# RT584ZCM33 register map
Series: ARMv8-M Mainline; File version: 1.0
CPU: CM33 r0p0, little endian, MPU, no FPU, VTOR, 3 interrupt priority bits
Registers are 32-bit, read-write, reset 0x0 unless marked. A register's access mark holds for its fields unless they carry their own. Offsets are from the block's base; [hi:lo] are bit positions.

## I2C_S_Non-Secure — I2C_S Non-Secure Register block
Base 0x40018000
Same registers: I2C_S_Secure 0x50018000
0x00 I2CS_RWDATA_REG — i2cs rwdata
  [7:0] rx_data ro — Received Data
    0=B_0_to_7 (Received Data)
  [7:0] tx_data wo — Data To be transmitted
0x04 I2CS_ADDR_REG — i2cs addr
  [7:1] slv_addr — I2C Slave address
    0=B_1_to_7 (I2C Slave address)
0x08 I2CS_IER_REG — i2cs ier
  [5:0] i2cs_intr_en — Enable of interrupts. Set 1 to enable intr_status trigger interrupts. [0] Address Match Interrupt. [1] Data Ready Interrupt. [2] bus_stop Interrupt. [3] Timeout Interrupt. [4] NA [5] NA
    0=B_0_to_5 (Enable of interrupts. Set 1 to enable intr_status trigger interrupts. [0] Address Match Interrupt. [1] Data Ready Interrupt. [2] bus_stop Interrupt. [3] Timeout Interrupt. [4] NA [5] NA)
0x0C I2CS_ISR_REG — i2cs isr
  [5:0] i2cs_intr_status ro — Status of interrupts. These bits still work even when intr_en=0 [0] Address Match Interrupt. [1] Data Ready Interrupt. [2] bus_stop Interrupt. [3] Timeout Interrupt. [4] NA [5] NA
    0=B_0_to_5 (Status of interrupts. These bits still work even when intr_en=0 [0] Address Match Interrupt. [1] Data Ready Interrupt. [2] bus_stop Interrupt. [3] Timeout Interrupt. [4] NA [5] NA)
  [5:0] i2cs_intr_clr wo — Interrupts clear signal. Write 1 to clear intr_status for each bit
    0=B_0_to_5 (Interrupts clear signal. Write 1 to clear intr_status for each bit)
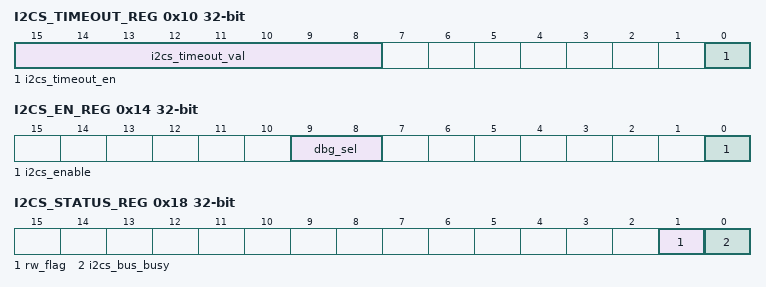
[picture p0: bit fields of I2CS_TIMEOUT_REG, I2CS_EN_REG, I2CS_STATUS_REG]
0x10 I2CS_TIMEOUT_REG — i2cs timeout
  [15:8] i2cs_timeout_val — Timeout value = (1 + timeout_val) ms
    0=B_8_to_15 (Timeout value = (1 + timeout_val) ms)
  [0] i2cs_timeout_en — Enable timeout function when SCL being not changed for 1~256ms
    0=B_0 (Enable timeout function when SCL being not changed for 1~256ms)
0x14 I2CS_EN_REG — i2cs en
  [9:8] dbg_sel — debug sel
    0=B_8_to_9 (debug sel)
  [0] i2cs_enable — Set 1 to start I2C after all above setting is ready.
    0=B_0 (Set 1 to start I2C after all above setting is ready.)
0x18 I2CS_STATUS_REG ro — i2cs status
  [1] rw_flag — Read/Write flag of I2C spec. 0: write 1: read
    0=B_1_ITEM0 (write); 1=B_1_ITEM1 (read)
  [0] i2cs_bus_busy — busy. Assert when bus start detected. Deassert when bus stop detected.
    0=B_0 (busy. Assert when bus start detected. Deassert when bus stop detected.)

## xDMA_Non-Secure — xDMA Non-Secure Register block
Base 0x40028000
Same registers: xDMA_Secure 0x50028000
0x00 CTL0_REG reset 0x1 — ctl0
  [0] cfg_xdma_en — Enable XDMA 0: disable 1: enable
    0=B_0_ITEM0 (disable); 1=B_0_ITEM1 (enable)
0x04 CTL1_REG wo — ctl1
  [0] cfg_xdma_rst — Reset XDMA 0: disable 1: reset
    0=B_0 (Reset XDMA 0: disable 1: reset)

## DMA0_Non-Secure — DMA0 Non-Secure Register block
Base 0x40029000
Same registers: DMA1_Non-Secure 0x4002A000, DMA0_Secure 0x50029000, DMA1_Secure 0x5002A000
0x00 READ_SRC_ADDR_REG — read source address
0x04 WRITE_DES_ADDR_REG — write desination address
0x08 MOVE_BYTE_COUNT_REG reset 0x1 — move byte, need >= 1
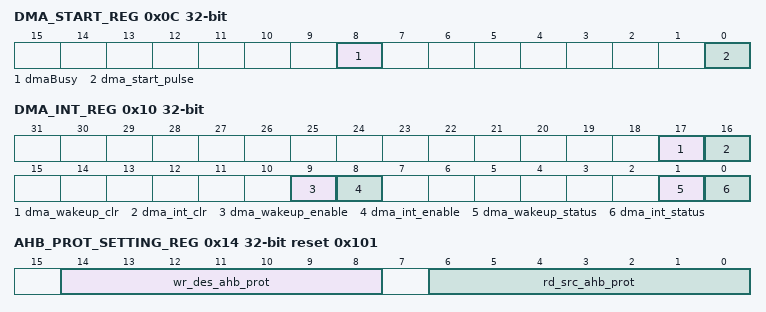
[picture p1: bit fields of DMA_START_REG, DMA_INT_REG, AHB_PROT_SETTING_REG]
0x0C DMA_START_REG — dma start
  [8] dmaBusy ro
    0=B_8 (dma busy)
  [0] dma_start_pulse wo — start engine
    0=B_0 (start engine)
0x10 DMA_INT_REG — dma int
  [17] dma_wakeup_clr wo — wakeup clear
    0=B_17 (wakeup clear)
  [16] dma_int_clr wo — interrupt clear
    0=B_16 (interrupt clear)
  [9] dma_wakeup_enable — wakeup enable
    0=B_9 (wakeup enable)
  [8] dma_int_enable — interrupt enable
    0=B_8 (interrupt enable)
  [1] dma_wakeup_status ro — wakeup status
    0=B_1 (wakeup status)
  [0] dma_int_status ro — interrupt status
    0=B_0 (interrupt status)
0x14 AHB_PROT_SETTING_REG reset 0x101 — ahb prot setting
  [14:8] wr_des_ahb_prot — write ahb bus prot
    0=B_8_to_14 (write ahb bus prot)
  [6:0] rd_src_ahb_prot — read ahb bus prot
    0=B_0_to_6 (read ahb bus prot)
